# nrf9220_cellcore register map
Vendor: Nordic Semiconductor; Series: nRF92; File version: 1
CPU: CM33 r0p4, little endian, MPU, FPU, 3 interrupt priority bits, 480 interrupts, 8 SAU regions
Registers are 32-bit, read-write, reset 0x0 unless marked. A register's access mark holds for its fields unless they carry their own. Offsets are from the block's base; [hi:lo] are bit positions; 'fields as' and 'values as' point back to an identical list.

## SACR_NS — Sample accumulator router 0
Base 0x4400F000
Same registers: SACR_S 0x5400F000
0x00 TASKS_START wo — Start SACR
  [0] TASKS_START
    1=Trigger task
0x04 TASKS_STOP wo — Stop SACR
  [0] TASKS_STOP
    1=Trigger task
0x100 EVENTS_STARTED — SACR started
  [0] EVENTS_STARTED
    0=NotGenerated (Event not generated); 1=Generated (Event generated)
0x104 EVENTS_STOPPED — SACR stopped
  [0] EVENTS_STOPPED
    values as EVENTS_STARTED.EVENTS_STARTED
0x108 EVENTS_OVERFLOWERROR — Internal buffer not written out by AHB bus master when new data arrives from accumulator
  [0] EVENTS_OVERFLOWERROR
    values as EVENTS_STARTED.EVENTS_STARTED
0x10C EVENTS_AHBSTOPPED — AHB bus master stopped
  [0] EVENTS_AHBSTOPPED
    values as EVENTS_STARTED.EVENTS_STARTED
0x110 EVENTS_AHBBUSERROR — This event is generated if an error occurs during the AHB bus master bus transfer This event is generated on an AHB / AXI error response
  [0] EVENTS_AHBBUSERROR
    values as EVENTS_STARTED.EVENTS_STARTED
0x200 SHORTS — Shortcuts between local events and tasks
  [0] AHBBUSERROR_STOP — Shortcut between event AHBBUSERROR and task STOP
    0=Disabled (Disable shortcut); 1=Enabled (Enable shortcut)
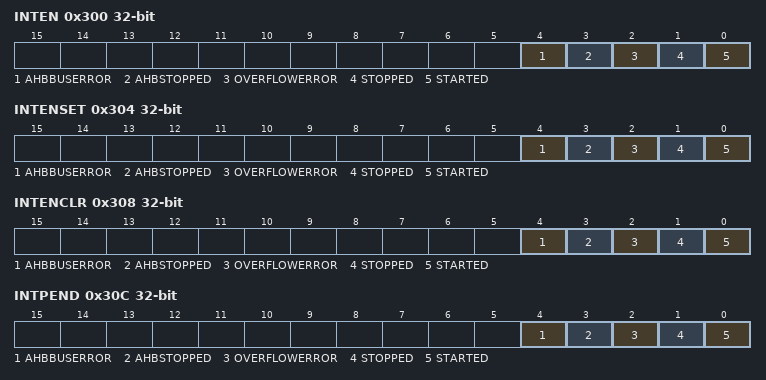
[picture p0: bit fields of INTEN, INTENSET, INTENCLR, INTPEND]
0x300 INTEN — Enable or disable interrupt
  [all] fields
    0=Disabled; 1=Enabled
  [4] AHBBUSERROR — Enable or disable interrupt for event AHBBUSERROR
  [3] AHBSTOPPED — Enable or disable interrupt for event AHBSTOPPED
  [2] OVERFLOWERROR — Enable or disable interrupt for event OVERFLOWERROR
  [1] STOPPED — Enable or disable interrupt for event STOPPED
  [0] STARTED — Enable or disable interrupt for event STARTED
0x304 INTENSET — Enable interrupt
  [all] fields
    on read: 0=Disabled (Read: Disabled); 1=Enabled (Read: Enabled) | on write: 1=Set (Enable)
  [4] AHBBUSERROR — Write '1' to enable interrupt for event AHBBUSERROR
  [3] AHBSTOPPED — Write '1' to enable interrupt for event AHBSTOPPED
  [2] OVERFLOWERROR — Write '1' to enable interrupt for event OVERFLOWERROR
  [1] STOPPED — Write '1' to enable interrupt for event STOPPED
  [0] STARTED — Write '1' to enable interrupt for event STARTED
0x308 INTENCLR — Disable interrupt
  [all] fields
    on read: 0=Disabled (Read: Disabled); 1=Enabled (Read: Enabled) | on write: 1=Clear (Disable)
  [4] AHBBUSERROR — Write '1' to disable interrupt for event AHBBUSERROR
  [3] AHBSTOPPED — Write '1' to disable interrupt for event AHBSTOPPED
  [2] OVERFLOWERROR — Write '1' to disable interrupt for event OVERFLOWERROR
  [1] STOPPED — Write '1' to disable interrupt for event STOPPED
  [0] STARTED — Write '1' to disable interrupt for event STARTED
0x30C INTPEND ro — Pending interrupts
  [all] fields
    on read: 0=NotPending (Read: Not pending); 1=Pending (Read: Pending)
  [4] AHBBUSERROR — Read pending status of interrupt for event AHBBUSERROR
  [3] AHBSTOPPED — Read pending status of interrupt for event AHBSTOPPED
  [2] OVERFLOWERROR — Read pending status of interrupt for event OVERFLOWERROR
  [1] STOPPED — Read pending status of interrupt for event STOPPED
  [0] STARTED — Read pending status of interrupt for event STARTED
0x500 MODE — Channel mode
  [1:0] MODE
    0=Dual (Both channel 0 and 1 in use); 1=Ch0 (Channel 0 only in use); 2=Ch1 (Channel 1 only in use); 3=Test (Reserved for test use)
0x504 ACCUSIZE reset 0x3 — Accumulator size
  [3:0] ACCUSIZE
0x508 PTR — Memory pointer
0x50C MAXCNT reset 0x1 — Transfer size
  [2:0] MAXCNT
0x510 TERMINATEONBUSERROR reset 0x1 — Terminate the AHB bus master transaction if a BUSERROR event is detected
  [0] ENABLE
    0=Disabled; 1=Enabled
0x514 BUSERRORADDRESS ro reset 0x1 — Address of AHB bus master transaction that generated the last BUSERROR event
  [31:0] ADDRESS
0x518 TESTDATA0 — Test data register channel 0
  [15:0] TESTDATA0
0x51C TESTDATA1 — Test data register channel 1
  [15:0] TESTDATA1
0x520 RESULTMODE — Result output mode
  [1:0] RESULTMODE
    0=Bus (Write results to bus only); 1=BusAndReg (Write results to bus and internal APB registers); 2=Reg (Write results to internal APB registers only); 3=Illegal
0x524 RESULT0 — Result register 0
0x528 RESULT1 — Result register 1
0x52C FORCEBUSCKREQ — Force register for reqBusCk output
  [0] FORCEBUSCKREQ
    0=Core drives clock request high when needed; 1=Force (Clock request output is constantly 1)
